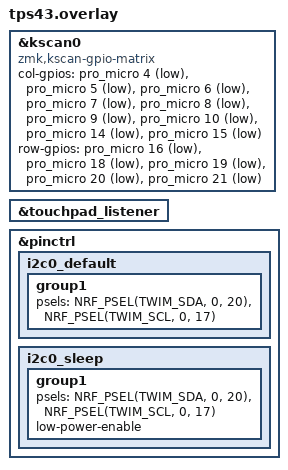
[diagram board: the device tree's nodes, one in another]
#include "tps43.dtsi"
#include "tps43_touchpad.dtsi"
#include "tps43_iqs5xx.dtsi"

// ─── TPS43 FPC connector order (SDA/SCL physically swapped on board) ─────────
//   SDA wire → P0.20  pro_micro 3  (pinctrl overridden below)
//   SCL wire → P0.17  pro_micro 2  (pinctrl overridden below)
//   3V3 → VCC
//   GND → GND
//   RST → P0.08  pro_micro 0  (GPIO_ACTIVE_LOW)
//   RDY → P0.06  pro_micro 1  (GPIO_ACTIVE_HIGH)
//
// ─── GPIO matrix — 14 remaining pins, all sequential ─────────────────────────
//   Cols  4-10, 14-15 → D4-D10, D14-D15  (9 pins)
//   Rows  16, 18-21   → D16, A0-A3       (5 pins)

&kscan0 {
    compatible = "zmk,kscan-gpio-matrix";

    col-gpios
        = <&pro_micro  4 (GPIO_ACTIVE_LOW | GPIO_PULL_UP)>  /* col 0 — P0.22  D4  */
        , <&pro_micro  5 (GPIO_ACTIVE_LOW | GPIO_PULL_UP)>  /* col 1 — P0.24  D5  */
        , <&pro_micro  6 (GPIO_ACTIVE_LOW | GPIO_PULL_UP)>  /* col 2 — P1.00  D6  */
        , <&pro_micro  7 (GPIO_ACTIVE_LOW | GPIO_PULL_UP)>  /* col 3 — P0.11  D7  */
        , <&pro_micro  8 (GPIO_ACTIVE_LOW | GPIO_PULL_UP)>  /* col 4 — P1.04  D8  */
        , <&pro_micro  9 (GPIO_ACTIVE_LOW | GPIO_PULL_UP)>  /* col 5 — P1.06  D9  */
        , <&pro_micro 10 (GPIO_ACTIVE_LOW | GPIO_PULL_UP)>  /* col 6 — P0.09  D10 */
        , <&pro_micro 14 (GPIO_ACTIVE_LOW | GPIO_PULL_UP)>  /* col 7 — P1.11  D14 */
        , <&pro_micro 15 (GPIO_ACTIVE_LOW | GPIO_PULL_UP)>  /* col 8 — P1.13  D15 */
        ;

    row-gpios
        = <&pro_micro 16 GPIO_ACTIVE_LOW>  /* row 0 — P0.10  D16 */
        , <&pro_micro 18 GPIO_ACTIVE_LOW>  /* row 1 — P1.15  A0  */
        , <&pro_micro 19 GPIO_ACTIVE_LOW>  /* row 2 — P0.02  A1  */
        , <&pro_micro 20 GPIO_ACTIVE_LOW>  /* row 3 — P0.29  A2  */
        , <&pro_micro 21 GPIO_ACTIVE_LOW>  /* row 4 — P0.31  A3  */
        ;
};

&touchpad_listener {
    status = "okay";
};

// Swap SDA↔SCL to match physical wiring (pins soldered inverted).
&pinctrl {
    i2c0_default: i2c0_default {
        group1 {
            psels = <NRF_PSEL(TWIM_SDA, 0, 20)>,   /* P0.20 — actual SDA wire */
                    <NRF_PSEL(TWIM_SCL, 0, 17)>;    /* P0.17 — actual SCL wire */
        };
    };
    i2c0_sleep: i2c0_sleep {
        group1 {
            psels = <NRF_PSEL(TWIM_SDA, 0, 20)>,
                    <NRF_PSEL(TWIM_SCL, 0, 17)>;
            low-power-enable;
        };
    };
};
